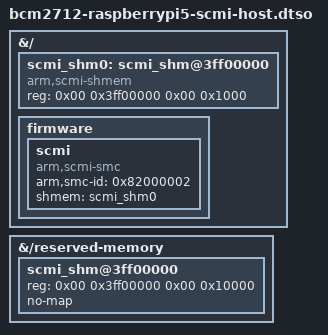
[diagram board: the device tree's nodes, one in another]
// SPDX-License-Identifier: GPL-2.0
/*
 * HOST (hypervisor) DT overlay that publishes the TF-A SCMI server to Xen.
 *
 * Why this file exists instead of the upstream bcm2712-raspberrypi5-xen-scmi.dtso
 * that meta-xt-driver-domain used to ship (removed as never loaded):
 *
 *  1. The upstream overlay sets `#size-cells = <0x01>` on the ROOT node so that its
 *     `reg = <0x0 0x3ff00000 0x10000>` parses. bcm2712-rpi-5-b.dtb is 2/2, and every
 *     root child (/soc@107c000000, /axi, /reserved-memory, ...) encodes its `ranges`
 *     with the ROOT size-cells. Flipping root to 2/1 silently reinterprets all of
 *     them. This file keeps 2/2 and writes a 4-cell reg.
 *  2. The upstream overlay writes `xen,arm_sci = "scmi_smc"` on /chosen/domD. That is
 *     the EPAM downstream property name; upstream Xen, which is what this build uses,
 *     reads `xen,sci_type` (domu_dt_sci_parse() in xen/arch/arm/dom0less-build.c).
 *     That property is the DOMAIN half and is not this overlay's business: publishing
 *     the server here is necessary but not sufficient, and a domain becomes an SCI
 *     agent only once the boot script writes `xen,sci_type = "scmi_smc"` onto its
 *     /chosen/<domain> node.
 *  3. The upstream overlay also rewrites &pcie1/&pcie2 resets to <&scmi_reset ...> and
 *     retargets /pwr_button. Those belong to a Linux Dom0 that drives SCMI itself; this
 *     board runs a Zephyr Dom0 and hands SCMI to DomD, so they are deliberately absent.
 *
 * What Xen needs from the host DT, and nothing more:
 *   - a node with compatible "arm,scmi-smc" carrying "arm,smc-id", so the
 *     DEVICE_FIRMWARE probe (scmi_dom0_init() in xen/arch/arm/firmware/scmi-smc.c)
 *     registers the SCI mediator. Without it `xen,sci_type = "scmi_smc"` on a domain
 *     fails and the domain is not created.
 *   - it must sit at exactly /firmware/scmi: scmi_smc_dt_handle_node() matches that
 *     path (DT_MATCH_PATH) to skip the node when generating Dom0's DT and to grant
 *     Dom0 iomem access to the shmem window instead.
 *   - the shmem window must be reserved so Xen does not hand that RAM to a guest.
 *
 * Addresses are fixed by TF-A, not chosen here: plat/rpi/rpi5/platform.mk sets
 * RPI_SCMI_SHMEM_BASE := 0x3ff00000 / RPI_SCMI_SHMEM_SIZE := 0x10000 and
 * plat/rpi/rpi5/scmi/scmi.c lays out 8 agent channels at base + n * PAGE_SIZE.
 * plat/rpi/rpi5/include/rpi5_smc.h sets RPI5_SIP_SMC_SCMI 0x82000002 = agent 0.
 * The whole 64 KiB is reserved; only agent 0's page is mapped into DomD (see
 * bcm2712-raspberrypi5-domd-vc4.dts).
 */
/dts-v1/;
/plugin/;

&{/} {
	/* Restated, not changed: bcm2712-rpi-5-b.dtb is already 2/2 here. dtc cannot
	 * see the target node from inside an overlay fragment and would otherwise
	 * validate the 4-cell regs below against its 2/1 default and warn. */
	#address-cells = <0x02>;
	#size-cells = <0x02>;

	/*
	 * Agent 0's SCMI shared-memory channel. Flat node (no mmio-sram wrapper):
	 * the only consumer is the `shmem` phandle below plus DomD's own copy, and a
	 * wrapper would force a second address translation for no benefit.
	 */
	scmi_shm0: scmi_shm@3ff00000 {
		compatible = "arm,scmi-shmem";
		reg = <0x00 0x3ff00000 0x00 0x1000>;
	};

	firmware {
		scmi {
			compatible = "arm,scmi-smc";
			/* = RPI5_SIP_SMC_SCMI. SiP-owner fast SMC, so Xen's vsmc
			 * layer routes it to the SCI mediator (vsmc.c:301 ->
			 * handle_sip() -> sci_handle_call()). */
			arm,smc-id = <0x82000002>;
			#address-cells = <0x01>;
			#size-cells = <0x00>;
			shmem = <&scmi_shm0>;
		};
	};
};

&{/reserved-memory} {
	#address-cells = <0x02>;
	#size-cells = <0x02>;

	/*
	 * Keep the full TF-A channel window out of Xen's allocator. Note that
	 * boot.cmd removes the VideoCore framebuffer reservation at 0x3f800000,
	 * whose 8 MiB span reaches 0x40000000 and therefore covers this window --
	 * that is exactly why an explicit reservation is required here.
	 */
	scmi_shm@3ff00000 {
		reg = <0x00 0x3ff00000 0x00 0x10000>;
		no-map;
	};
};
